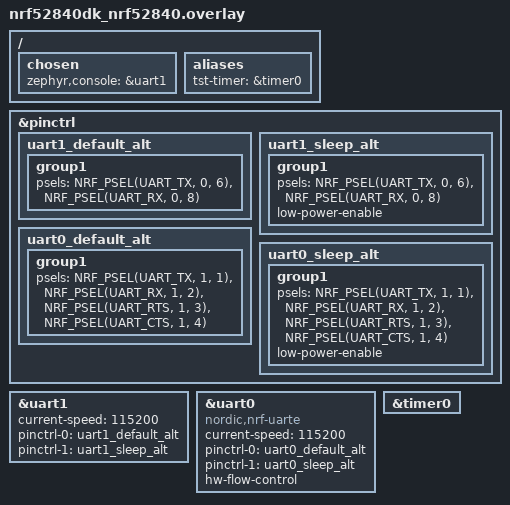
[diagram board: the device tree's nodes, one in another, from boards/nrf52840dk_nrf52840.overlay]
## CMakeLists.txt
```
#
# Copyright (c) 2025 Nordic Semiconductor ASA
#
# SPDX-License-Identifier: LicenseRef-Nordic-5-Clause
#

cmake_minimum_required(VERSION 3.20.0)

find_package(Zephyr REQUIRED HINTS $ENV{ZEPHYR_BASE})

if(NOT SYSBUILD)
	message(FATAL_ERROR
		" This is a multi-image application that should be built using sysbuild.\n"
		" Add --sysbuild argument to west build command to prepare all the images.")
endif()

project(uart_latency)

if(CONFIG_UART_INTERRUPT_DRIVEN)
	FILE(GLOB app_sources src/int_driven.c)
elseif(CONFIG_UART_ASYNC_API)
	FILE(GLOB app_sources src/async.c)
else()
	FILE(GLOB app_sources src/polling.c)
endif()

target_sources(app PRIVATE src/common.c ${app_sources})
```

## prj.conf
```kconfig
CONFIG_SERIAL=y
CONFIG_UART_USE_RUNTIME_CONFIGURE=y

CONFIG_ZTEST=y
CONFIG_DK_LIBRARY=y
CONFIG_COUNTER=y
```

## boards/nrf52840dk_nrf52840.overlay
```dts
/*
 * Copyright (c) 2025 Nordic Semiconductor ASA
 *
 * SPDX-License-Identifier: LicenseRef-Nordic-5-Clause
 */

/ {
	chosen {
		zephyr,console = &uart1;
	};
	aliases {
		tst-timer = &timer0;
	};
};

&pinctrl {
	uart1_default_alt: uart1_default_alt {
		group1 {
			psels = <NRF_PSEL(UART_TX, 0, 6)>,
				<NRF_PSEL(UART_RX, 0, 8)>;
		};
	};

	uart1_sleep_alt: uart1_sleep_alt {
		group1 {
			psels = <NRF_PSEL(UART_TX, 0, 6)>,
				<NRF_PSEL(UART_RX, 0, 8)>;
			low-power-enable;
		};
	};

	uart0_default_alt: uart0_default_alt {
		group1 {
			psels = <NRF_PSEL(UART_TX, 1, 1)>,
				<NRF_PSEL(UART_RX, 1, 2)>,
				<NRF_PSEL(UART_RTS, 1, 3)>,
				<NRF_PSEL(UART_CTS, 1, 4)>;
		};
	};

	uart0_sleep_alt: uart0_sleep_alt {
		group1 {
			psels = <NRF_PSEL(UART_TX, 1, 1)>,
				<NRF_PSEL(UART_RX, 1, 2)>,
				<NRF_PSEL(UART_RTS, 1, 3)>,
				<NRF_PSEL(UART_CTS, 1, 4)>;
			low-power-enable;
		};
	};
};

&uart1 {
	current-speed = <115200>;
	status = "okay";
	pinctrl-0 = <&uart1_default_alt>;
	pinctrl-1 = <&uart1_sleep_alt>;
	pinctrl-names = "default", "sleep";
};

dut: &uart0 {
	compatible = "nordic,nrf-uarte";
	current-speed = <115200>;
	status = "okay";
	pinctrl-0 = <&uart0_default_alt>;
	pinctrl-1 = <&uart0_sleep_alt>;
	pinctrl-names = "default", "sleep";
	hw-flow-control;
};

&timer0 {
	status = "okay";
};
```

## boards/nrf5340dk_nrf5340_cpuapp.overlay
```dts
/*
 * Copyright (c) 2025 Nordic Semiconductor ASA
 *
 * SPDX-License-Identifier: LicenseRef-Nordic-5-Clause
 */

/ {
	aliases {
		tst-timer = &timer0;
	};
};

&pinctrl {
	uart1_default_alt: uart1_default_alt {
		group1 {
			psels = <NRF_PSEL(UART_TX, 0, 4)>,
				<NRF_PSEL(UART_RX, 0, 5)>,
				<NRF_PSEL(UART_RTS, 0, 6)>,
				<NRF_PSEL(UART_CTS, 0, 7)>;
		};
	};

	uart1_sleep_alt: uart1_sleep_alt {
		group1 {
			psels = <NRF_PSEL(UART_TX, 0, 4)>,
				<NRF_PSEL(UART_RX, 0, 5)>,
				<NRF_PSEL(UART_RTS, 0, 6)>,
				<NRF_PSEL(UART_CTS, 0, 7)>;
			low-power-enable;
		};
	};
};

&timer0 {
	status = "okay";
};

dut: &uart1 {
	current-speed = <115200>;
	compatible = "nordic,nrf-uarte";
	status = "okay";
	pinctrl-0 = <&uart1_default_alt>;
	pinctrl-1 = <&uart1_sleep_alt>;
	pinctrl-names = "default", "sleep";
	hw-flow-control;
};
```

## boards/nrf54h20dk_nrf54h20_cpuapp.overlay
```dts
/*
 * Copyright (c) 2025 Nordic Semiconductor ASA
 *
 * SPDX-License-Identifier: LicenseRef-Nordic-5-Clause
 */

/ {
	aliases {
		tst-timer = &timer130;
	};
};

/* UART device used for test
 * not the default UART assignment for the LD
 */
&pinctrl {
	uart135_default_alt: uart135_default_alt {
		group1 {
			psels = <NRF_PSEL(UART_TX, 0, 6)>,
				<NRF_PSEL(UART_RX, 0, 7)>,
				<NRF_PSEL(UART_RTS, 0, 8)>,
				<NRF_PSEL(UART_CTS, 0, 9)>;
		};
	};

	uart135_sleep_alt: uart135_sleep_alt {
		group1 {
			psels = <NRF_PSEL(UART_TX, 0, 6)>,
				<NRF_PSEL(UART_RX, 0, 7)>,
				<NRF_PSEL(UART_RTS, 0, 8)>,
				<NRF_PSEL(UART_CTS, 0, 9)>;
			low-power-enable;
		};
	};
};

&cpuapp_dma_region {
	status="okay";
};

&timer130 {
	status = "okay";
};

dut: &uart135 {
	status = "okay";
	memory-regions = <&cpuapp_dma_region>;
	pinctrl-0 = <&uart135_default_alt>;
	pinctrl-1 = <&uart135_sleep_alt>;
	pinctrl-names = "default", "sleep";
	current-speed = <115200>;
	hw-flow-control;
};
```

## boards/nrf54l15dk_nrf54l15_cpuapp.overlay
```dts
/*
 * Copyright (c) 2025 Nordic Semiconductor ASA
 *
 * SPDX-License-Identifier: LicenseRef-Nordic-5-Clause
 */

/ {
	aliases {
		tst-timer = &timer20;
	};
};

&pinctrl {
	uart21_default: uart21_default {
		group1 {
			psels = <NRF_PSEL(UART_TX, 1, 10)>,
				<NRF_PSEL(UART_RX, 1, 11)>,
				<NRF_PSEL(UART_RTS, 1, 8)>,
				<NRF_PSEL(UART_CTS, 1, 9)>;
		};
	};

	uart21_sleep: uart21_sleep {
		group1 {
			psels = <NRF_PSEL(UART_TX, 1, 10)>,
				<NRF_PSEL(UART_RX, 1, 11)>,
				<NRF_PSEL(UART_RTS, 1, 8)>,
				<NRF_PSEL(UART_CTS, 1, 9)>;
			low-power-enable;
		};
	};
};

&timer20 {
	status = "okay";
};

dut: &uart21 {
	status = "okay";
	current-speed = <115200>;
	pinctrl-0 = <&uart21_default>;
	pinctrl-1 = <&uart21_sleep>;
	pinctrl-names = "default", "sleep";
	hw-flow-control;
};
```

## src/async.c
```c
/*
 * Copyright (c) 2025 Nordic Semiconductor ASA
 *
 * SPDX-License-Identifier: LicenseRef-Nordic-5-Clause
 */

#include "common.h"

static K_SEM_DEFINE(uart_rx_ready_sem, 0, 1);
static K_SEM_DEFINE(uart_tx_done_sem, 0, 1);

extern const struct device *const uart_dev;
extern const struct device *const tst_timer_dev;
extern uint8_t tx_test_buffer[MAX_BUFFER_SIZE];
extern uint8_t rx_test_buffer[MAX_BUFFER_SIZE];

static void async_uart_callback(const struct device *dev, struct uart_event *evt, void *user_data)
{
	switch (evt->type) {
	case UART_TX_DONE:
		k_sem_give(&uart_tx_done_sem);
		break;
	case UART_TX_ABORTED:
		break;
	case UART_RX_RDY:
		k_sem_give(&uart_rx_ready_sem);
		break;
	case UART_RX_BUF_RELEASED:
		break;
	case UART_RX_BUF_REQUEST:
		break;
	case UART_RX_DISABLED:
		break;
	default:
		break;
	}
}

static void enable_uart_rx(uart_test_data *test_data)
{
	int err;

	do {
		err = uart_rx_enable(uart_dev, test_data->rx_buffer, test_data->buffer_size,
				     UART_TIMEOUT_US);
	} while (err == -EBUSY);
	zassert_equal(err, 0, "Unexpected error when enabling UART RX: %d");
}

static void test_uart_latency(size_t buffer_size, uint32_t baudrate)
{
	int err;
	uint32_t tst_timer_value;
	uint64_t timer_value_us;
	uint32_t theoretical_transmission_time_us;
	uint32_t maximal_allowed_transmission_time_us;
	struct uart_config test_uart_config;
	uart_test_data test_data;

	test_data.tx_buffer = tx_test_buffer;
	test_data.rx_buffer = rx_test_buffer;
	test_data.buffer_size = buffer_size;

	zassert_true(buffer_size <= MAX_BUFFER_SIZE,
		     "Given buffer size is to big, allowed max %u bytes\n", MAX_BUFFER_SIZE);

	TC_PRINT("UART TX latency in ASYNC mode test with buffer size: %u bytes and baudrate: %u\n",
		 buffer_size, baudrate);
	set_test_pattern(&test_data);
	err = uart_config_get(uart_dev, &test_uart_config);
	zassert_equal(err, 0, "Failed to get uart config");
	test_uart_config.baudrate = baudrate;
	err = uart_configure(uart_dev, &test_uart_config);
	zassert_equal(err, 0, "UART configuration failed");
	err = uart_callback_set(uart_dev, async_uart_callback, NULL);
	zassert_equal(err, 0, "UART callback setup failed");

	theoretical_transmission_time_us =
		calculate_theoretical_transsmison_time_us(&test_uart_config, buffer_size);
	maximal_allowed_transmission_time_us = MAX_TOLERANCE * theoretical_transmission_time_us;

	configure_test_timer(tst_timer_dev, TEST_TIMER_COUNT_TIME_LIMIT_MS);
	counter_reset(tst_timer_dev);
	enable_uart_rx(&test_data);
	dk_set_led_on(DK_LED1);

	counter_start(tst_timer_dev);
	err = uart_tx(uart_dev, test_data.tx_buffer, buffer_size, UART_TIMEOUT_US);
	while (k_sem_take(&uart_tx_done_sem, K_NO_WAIT) != 0) {
	};
	counter_get_value(tst_timer_dev, &tst_timer_value);
	counter_stop(tst_timer_dev);
	dk_set_led_off(DK_LED1);
	timer_value_us = counter_ticks_to_us(tst_timer_dev, tst_timer_value);
	zassert_equal(err, 0, "UART transmission failed");

	while (k_sem_take(&uart_rx_ready_sem, K_NO_WAIT) != 0) {
	};
	check_transmitted_data(&test_data);

	TC_PRINT("Calculated transmission time (for %u bytes) [us]: %u\n", buffer_size,
		 theoretical_transmission_time_us);
	TC_PRINT("Measured transmission time (for %u bytes) [us]: %llu\n", buffer_size,
		 timer_value_us);
	TC_PRINT("Measured - claculated time delta (for %d bytes) [us]: %lld\n", buffer_size,
		 timer_value_us - theoretical_transmission_time_us);
	TC_PRINT("Maximal allowed transmission time [us]: %u\n",
		 maximal_allowed_transmission_time_us);

	zassert_true(timer_value_us < maximal_allowed_transmission_time_us,
		     "Measured call latency is over the specified limit");
}

ZTEST(uart_latency, test_uart_latency_in_async_mode_baud_9k6)
{
	test_uart_latency(10, UART_BAUD_9k6);
	test_uart_latency(128, UART_BAUD_9k6);
	test_uart_latency(1024, UART_BAUD_9k6);
	test_uart_latency(3000, UART_BAUD_9k6);
}

ZTEST(uart_latency, test_uart_latency_in_async_mode_baud_115k2)
{
	test_uart_latency(10, UART_BAUD_115k2);
	test_uart_latency(128, UART_BAUD_115k2);
	test_uart_latency(1024, UART_BAUD_115k2);
	test_uart_latency(3000, UART_BAUD_115k2);
}

ZTEST(uart_latency, test_uart_latency_in_async_mode_baud_921k6)
{
	test_uart_latency(10, UART_BAUD_921k6);
	test_uart_latency(128, UART_BAUD_921k6);
	test_uart_latency(1024, UART_BAUD_921k6);
	test_uart_latency(3000, UART_BAUD_921k6);
}

void *test_setup(void)
{
	zassert_true(device_is_ready(uart_dev), "UART device is not ready");
	zassert_equal(dk_leds_init(), 0, "DK leds init failed");

	dk_set_led_off(DK_LED1);
	return NULL;
}

ZTEST_SUITE(uart_latency, NULL, test_setup, NULL, NULL, NULL);
```

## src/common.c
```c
/*
 * Copyright (c) 2025 Nordic Semiconductor ASA
 *
 * SPDX-License-Identifier: LicenseRef-Nordic-5-Clause
 */

#include "common.h"

const struct device *const uart_dev = DEVICE_DT_GET(UART_NODE);
const struct device *const tst_timer_dev = DEVICE_DT_GET(DT_ALIAS(tst_timer));

uint8_t tx_test_buffer[MAX_BUFFER_SIZE];
uint8_t rx_test_buffer[MAX_BUFFER_SIZE];

void set_test_pattern(uart_test_data *test_data)
{
	for (uint32_t counter = 0; counter < test_data->buffer_size; counter++) {
		test_data->tx_buffer[counter] = (uint8_t)(counter & 0xFF);
		test_data->rx_buffer[counter] = 0xFF;
	}
}

void configure_test_timer(const struct device *timer_dev, uint32_t count_time_ms)
{
	struct counter_alarm_cfg counter_cfg;

	counter_cfg.flags = 0;
	counter_cfg.ticks = counter_us_to_ticks(timer_dev, (uint64_t)count_time_ms * 1000);
	counter_cfg.user_data = &counter_cfg;
}

uint32_t calculate_theoretical_transsmison_time_us(struct uart_config *tst_uart_config,
						   size_t buffer_size)
{
	uint32_t number_of_bits;
	float ratio;

	number_of_bits = 1 + (tst_uart_config->data_bits + 5) + tst_uart_config->stop_bits;
	ratio = 1000000.0 / tst_uart_config->baudrate;
	return (uint32_t)(ratio * (float)number_of_bits * (float)buffer_size);
}

void check_transmitted_data(uart_test_data *test_data)
{
	for (int index = 0; index < test_data->buffer_size; index++) {
		zassert_equal(test_data->rx_buffer[index], test_data->tx_buffer[index],
			      "Received data byte %d does not match pattern 0x%x != 0x%x", index,
			      test_data->rx_buffer[index], test_data->tx_buffer[index]);
	}
}
```

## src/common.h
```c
/*
 * Copyright (c) 2025 Nordic Semiconductor ASA
 *
 * SPDX-License-Identifier: LicenseRef-Nordic-5-Clause
 */

#include <zephyr/ztest.h>
#include <zephyr/kernel.h>
#include <zephyr/drivers/gpio.h>
#include <dk_buttons_and_leds.h>
#include <zephyr/drivers/counter.h>
#include <zephyr/drivers/uart.h>

#define UART_TIMEOUT_US		       5000000
#define MAX_BUFFER_SIZE		       4096
#define TEST_TIMER_COUNT_TIME_LIMIT_MS 500
#define MAX_TOLERANCE		       2.0

#define UART_BAUD_9k6	9600
#define UART_BAUD_115k2 115200
#define UART_BAUD_921k6 921600

#if DT_NODE_EXISTS(DT_NODELABEL(dut))
#define UART_NODE DT_NODELABEL(dut)
#else
#error Improper device tree configuration, UART test node not available
#endif

typedef struct {
	uint8_t *tx_buffer;
	uint8_t *rx_buffer;
	size_t buffer_size;

} uart_test_data;

void set_test_pattern(uart_test_data *test_data);

void configure_test_timer(const struct device *timer_dev, uint32_t count_time_ms);

uint32_t calculate_theoretical_transsmison_time_us(struct uart_config *tst_uart_config,
						   size_t buffer_size);

void check_transmitted_data(uart_test_data *test_data);
```

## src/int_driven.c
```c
/*
 * Copyright (c) 2025 Nordic Semiconductor ASA
 *
 * SPDX-License-Identifier: LicenseRef-Nordic-5-Clause
 */

#include "common.h"

#define TX_TIMEOUT_MS 500

extern const struct device *const uart_dev;
extern const struct device *const tst_timer_dev;
extern uint8_t tx_test_buffer[MAX_BUFFER_SIZE];
extern uint8_t rx_test_buffer[MAX_BUFFER_SIZE];

static uint32_t tx_byte_offset;
static uint32_t rx_byte_offset;

K_SEM_DEFINE(uart_tx_done_sem, 0, 1);
K_SEM_DEFINE(uart_rx_done_sem, 0, 1);

void uart_tx_interrupt_service(const struct device *dev, uint8_t *test_pattern, size_t buffer_size,
			       uint32_t *tx_byte_offset)
{
	uint8_t bytes_sent = 0;
	uint8_t *tx_data_pointer = (uint8_t *)(test_pattern + *tx_byte_offset);

	if (*tx_byte_offset < buffer_size) {
		bytes_sent = uart_fifo_fill(dev, tx_data_pointer, 1);
		*tx_byte_offset += bytes_sent;
	} else {
		*tx_byte_offset = 0;
		k_sem_give(&uart_tx_done_sem);
		uart_irq_tx_disable(dev);
	}
}

void uart_rx_interrupt_service(const struct device *dev, uint8_t *receive_buffer_pointer,
			       size_t buffer_size, uint32_t *rx_byte_offset)
{
	int rx_data_length = 0;

	do {
		rx_data_length =
			uart_fifo_read(dev, receive_buffer_pointer + *rx_byte_offset, buffer_size);
		*rx_byte_offset += rx_data_length;
	} while (rx_data_length);
	if (*rx_byte_offset >= buffer_size) {
		*rx_byte_offset = 0;
		k_sem_give(&uart_rx_done_sem);
		uart_irq_rx_disable(uart_dev);
	}
}

void uart_isr_handler(const struct device *dev, void *user_data)
{
	uart_test_data *test_data = (uart_test_data *)user_data;

	uart_irq_update(dev);
	while (uart_irq_is_pending(dev)) {
		if (uart_irq_rx_ready(dev)) {
			uart_rx_interrupt_service(dev, test_data->rx_buffer, test_data->buffer_size,
						  &rx_byte_offset);
		}
		if (uart_irq_tx_ready(dev)) {
			uart_tx_interrupt_service(dev, test_data->tx_buffer, test_data->buffer_size,
						  &tx_byte_offset);
		}
	}
}

static void test_uart_latency(size_t buffer_size, uint32_t baudrate)
{
	int err;
	uint32_t tst_timer_value;
	uint64_t timer_value_us;
	uint32_t theoretical_transmission_time_us;
	uint32_t maximal_allowed_transmission_time_us;
	struct uart_config test_uart_config;
	uart_test_data test_data;

	test_data.buffer_size = buffer_size;
	test_data.tx_buffer = tx_test_buffer;
	test_data.rx_buffer = rx_test_buffer;
	test_data.buffer_size = buffer_size;

	tx_byte_offset = 0;
	rx_byte_offset = 0;

	zassert_true(buffer_size <= MAX_BUFFER_SIZE,
		     "Given buffer size is to big, allowed max %u bytes and baudrate: %u\n",
		     MAX_BUFFER_SIZE);

	TC_PRINT("UART TX latency in INTERRUPT mode test with buffer size: %u bytes and baudrate: "
		 "%u\n",
		 buffer_size, baudrate);

	set_test_pattern(&test_data);
	configure_test_timer(tst_timer_dev, TEST_TIMER_COUNT_TIME_LIMIT_MS);
	counter_reset(tst_timer_dev);

	err = uart_config_get(uart_dev, &test_uart_config);
	zassert_equal(err, 0, "Failed to get uart config");
	test_uart_config.baudrate = baudrate;
	err = uart_configure(uart_dev, &test_uart_config);
	zassert_equal(err, 0, "UART configuration failed");
	err = uart_irq_callback_set(uart_dev, uart_isr_handler);
	zassert_equal(err, 0, "Unexpected error when setting callback for LPUART %d", err);
	err = uart_irq_callback_user_data_set(uart_dev, uart_isr_handler, (void *)&test_data);
	zassert_equal(err, 0, "Unexpected error when setting user data for callback %d", err);

	theoretical_transmission_time_us =
		calculate_theoretical_transsmison_time_us(&test_uart_config, buffer_size);
	maximal_allowed_transmission_time_us = MAX_TOLERANCE * theoretical_transmission_time_us;

	uart_irq_err_enable(uart_dev);
	uart_irq_rx_enable(uart_dev);
	uart_irq_tx_enable(uart_dev);

	dk_set_led_on(DK_LED1);
	counter_start(tst_timer_dev);
	while (k_sem_take(&uart_tx_done_sem, K_NO_WAIT) != 0) {
	};
	counter_get_value(tst_timer_dev, &tst_timer_value);
	counter_stop(tst_timer_dev);
	dk_set_led_off(DK_LED1);
	timer_value_us = counter_ticks_to_us(tst_timer_dev, tst_timer_value);

	while (k_sem_take(&uart_rx_done_sem, K_NO_WAIT) != 0) {
	};

	uart_irq_err_disable(uart_dev);
	check_transmitted_data(&test_data);

	TC_PRINT("Calculated transmission time (for %u bytes) [us]: %u\n", buffer_size,
		 theoretical_transmission_time_us);
	TC_PRINT("Measured transmission time (for %u bytes) [us]: %llu\n", buffer_size,
		 timer_value_us);
	TC_PRINT("Measured - claculated time delta (for %u bytes) [us]: %lld\n", buffer_size,
		 timer_value_us - theoretical_transmission_time_us);
	TC_PRINT("Maximal allowed transmission time [us]: %u\n",
		 maximal_allowed_transmission_time_us);

	zassert_true(timer_value_us < maximal_allowed_transmission_time_us,
		     "Measured call latency is over the specified limit");
}

ZTEST(uart_latency, test_uart_latency_in_interrupt_mode_baud_9k6)
{
	test_uart_latency(10, UART_BAUD_9k6);
	test_uart_latency(128, UART_BAUD_9k6);
	test_uart_latency(1024, UART_BAUD_9k6);
	test_uart_latency(3000, UART_BAUD_9k6);
}

ZTEST(uart_latency, test_uart_latency_in_interrupt_mode_baud_115k2)
{
	test_uart_latency(10, UART_BAUD_115k2);
	test_uart_latency(128, UART_BAUD_115k2);
	test_uart_latency(1024, UART_BAUD_115k2);
	test_uart_latency(3000, UART_BAUD_115k2);
}

void *test_setup(void)
{
	zassert_true(device_is_ready(uart_dev), "UART device is not ready");
	zassert_equal(dk_leds_init(), 0, "DK leds init failed");

	dk_set_led_off(DK_LED1);
	return NULL;
}

ZTEST_SUITE(uart_latency, NULL, test_setup, NULL, NULL, NULL);
```

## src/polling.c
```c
/*
 * Copyright (c) 2025 Nordic Semiconductor ASA
 *
 * SPDX-License-Identifier: LicenseRef-Nordic-5-Clause
 */

#include "common.h"

extern const struct device *const uart_dev;
extern const struct device *const tst_timer_dev;
extern uint8_t tx_test_buffer[MAX_BUFFER_SIZE];
extern uint8_t rx_test_buffer[MAX_BUFFER_SIZE];

static void test_uart_latency(size_t buffer_size, uint32_t baudrate)
{
	int err;
	uint32_t tst_timer_value;
	uint64_t timer_value_us;
	uint32_t theoretical_transmission_time_us;
	uint32_t maximal_allowed_transmission_time_us;
	struct uart_config test_uart_config;
	uart_test_data test_data;

	test_data.buffer_size = buffer_size;
	test_data.tx_buffer = tx_test_buffer;
	test_data.rx_buffer = rx_test_buffer;
	test_data.buffer_size = buffer_size;

	zassert_true(buffer_size <= MAX_BUFFER_SIZE,
		     "Given buffer size is to big, allowed max %u bytes", MAX_BUFFER_SIZE);

	TC_PRINT("UART TX latency in POLLING mode test with buffer size: %u bytes and baudrate: "
		 "%u\n",
		 buffer_size, baudrate);

	set_test_pattern(&test_data);
	err = uart_config_get(uart_dev, &test_uart_config);
	zassert_equal(err, 0, "Failed to get uart config");
	test_uart_config.baudrate = baudrate;
	err = uart_configure(uart_dev, &test_uart_config);
	zassert_equal(err, 0, "UART configuration failed");

	theoretical_transmission_time_us =
		calculate_theoretical_transsmison_time_us(&test_uart_config, buffer_size);
	maximal_allowed_transmission_time_us = MAX_TOLERANCE * theoretical_transmission_time_us;

	configure_test_timer(tst_timer_dev, TEST_TIMER_COUNT_TIME_LIMIT_MS);
	counter_reset(tst_timer_dev);

	dk_set_led_on(DK_LED1);
	counter_start(tst_timer_dev);
	for (uint32_t counter = 0; counter < buffer_size; counter++) {
		uart_poll_out(uart_dev, test_data.tx_buffer[counter]);
		/* Wait for the character to be avilable in the RX buffer */
		while (uart_poll_in(uart_dev, &test_data.rx_buffer[counter]) == -1) {
		};
		uart_poll_in(uart_dev, &test_data.rx_buffer[counter]);
	}
	counter_get_value(tst_timer_dev, &tst_timer_value);
	counter_stop(tst_timer_dev);
	dk_set_led_off(DK_LED1);
	timer_value_us = counter_ticks_to_us(tst_timer_dev, tst_timer_value);
	check_transmitted_data(&test_data);

	TC_PRINT("Calculated transmission time (for %u bytes) [us]: %u\n", buffer_size,
		 theoretical_transmission_time_us);
	TC_PRINT("Measured transmission time (for %u bytes) [us]: %llu\n", buffer_size,
		 timer_value_us);
	TC_PRINT("Measured - claculated time delta (for %u bytes) [us]: %lld\n", buffer_size,
		 timer_value_us - theoretical_transmission_time_us);
	TC_PRINT("Maximal allowed transmission time [us]: %u\n",
		 maximal_allowed_transmission_time_us);

	zassert_true(timer_value_us < maximal_allowed_transmission_time_us,
		     "Measured call latency is over the specified limit");
}

ZTEST(uart_latency, test_uart_latency_in_polling_mode_baud_9k6)
{
	test_uart_latency(10, UART_BAUD_9k6);
	test_uart_latency(128, UART_BAUD_9k6);
	test_uart_latency(1024, UART_BAUD_9k6);
	test_uart_latency(3000, UART_BAUD_9k6);
}

ZTEST(uart_latency, test_uart_latency_in_polling_mode_baud_115k2)
{
	test_uart_latency(10, UART_BAUD_115k2);
	test_uart_latency(128, UART_BAUD_115k2);
	test_uart_latency(1024, UART_BAUD_115k2);
	test_uart_latency(3000, UART_BAUD_115k2);
}

ZTEST(uart_latency, test_uart_latency_in_polling_mode_baud_921k6)
{
	test_uart_latency(10, UART_BAUD_921k6);
	test_uart_latency(128, UART_BAUD_921k6);
	test_uart_latency(1024, UART_BAUD_921k6);
	test_uart_latency(3000, UART_BAUD_921k6);
}

void *test_setup(void)
{
	zassert_true(device_is_ready(uart_dev), "UART device is not ready");
	zassert_equal(dk_leds_init(), 0, "DK leds init failed");

	dk_set_led_off(DK_LED1);
	return NULL;
}

ZTEST_SUITE(uart_latency, NULL, test_setup, NULL, NULL, NULL);
```
